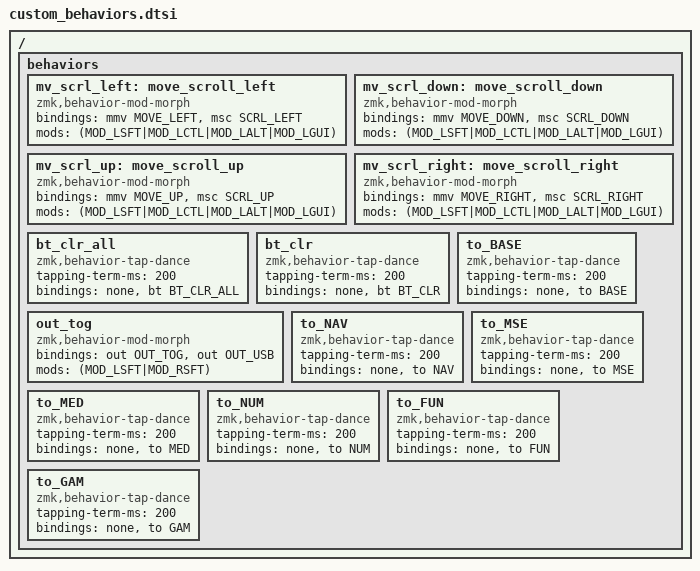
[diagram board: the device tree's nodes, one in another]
/ {
  behaviors {
    mv_scrl_left: move_scroll_left {
      compatible = "zmk,behavior-mod-morph";
      #binding-cells = <0>;
      bindings = <&mmv MOVE_LEFT>, <&msc SCRL_LEFT>;
      mods = <(MOD_LSFT|MOD_LCTL|MOD_LALT|MOD_LGUI)>;
    };

    mv_scrl_down: move_scroll_down {
      compatible = "zmk,behavior-mod-morph";
      #binding-cells = <0>;
      bindings = <&mmv MOVE_DOWN>, <&msc SCRL_DOWN>;
      mods = <(MOD_LSFT|MOD_LCTL|MOD_LALT|MOD_LGUI)>;
    };

    mv_scrl_up: move_scroll_up {
      compatible = "zmk,behavior-mod-morph";
      #binding-cells = <0>;
      bindings = <&mmv MOVE_UP>, <&msc SCRL_UP>;
      mods = <(MOD_LSFT|MOD_LCTL|MOD_LALT|MOD_LGUI)>;
    };

    mv_scrl_right: move_scroll_right {
      compatible = "zmk,behavior-mod-morph";
      #binding-cells = <0>;
      bindings = <&mmv MOVE_RIGHT>, <&msc SCRL_RIGHT>;
      mods = <(MOD_LSFT|MOD_LCTL|MOD_LALT|MOD_LGUI)>;
    };

    bt_clr_all: bt_clr_all {
      compatible = "zmk,behavior-tap-dance";
      #binding-cells = <0>;
      tapping-term-ms = <200>;
      bindings = <&none>, <&bt BT_CLR_ALL>;
    };

    bt_clr: bt_clr {
      compatible = "zmk,behavior-tap-dance";
      #binding-cells = <0>;
      tapping-term-ms = <200>;
      bindings = <&none>, <&bt BT_CLR>;
    };

    out_tog: out_tog {
      compatible = "zmk,behavior-mod-morph";
      #binding-cells = <0>;
      bindings = <&out OUT_TOG>, <&out OUT_USB>;
      mods = <(MOD_LSFT|MOD_RSFT)>;
    };

    to_BASE: to_BASE {
      compatible = "zmk,behavior-tap-dance";
      #binding-cells = <0>;
      tapping-term-ms = <200>;
      bindings = <&none>, <&to BASE>;
    };

    to_NAV: to_NAV {
      compatible = "zmk,behavior-tap-dance";
      #binding-cells = <0>;
      tapping-term-ms = <200>;
      bindings = <&none>, <&to NAV>;
    };

    to_MSE: to_MSE {
      compatible = "zmk,behavior-tap-dance";
      #binding-cells = <0>;
      tapping-term-ms = <200>;
      bindings = <&none>, <&to MSE>;
    };

    to_MED: to_MED {
      compatible = "zmk,behavior-tap-dance";
      #binding-cells = <0>;
      tapping-term-ms = <200>;
      bindings = <&none>, <&to MED>;
    };

    to_NUM: to_NUM {
      compatible = "zmk,behavior-tap-dance";
      #binding-cells = <0>;
      tapping-term-ms = <200>;
      bindings = <&none>, <&to NUM>;
    };

    to_FUN: to_FUN {
      compatible = "zmk,behavior-tap-dance";
      #binding-cells = <0>;
      tapping-term-ms = <200>;
      bindings = <&none>, <&to FUN>;
    };

    to_GAM: to_GAM {
      compatible = "zmk,behavior-tap-dance";
      #binding-cells = <0>;
      tapping-term-ms = <200>;
      bindings = <&none>, <&to GAM>;
    };
  };
};
